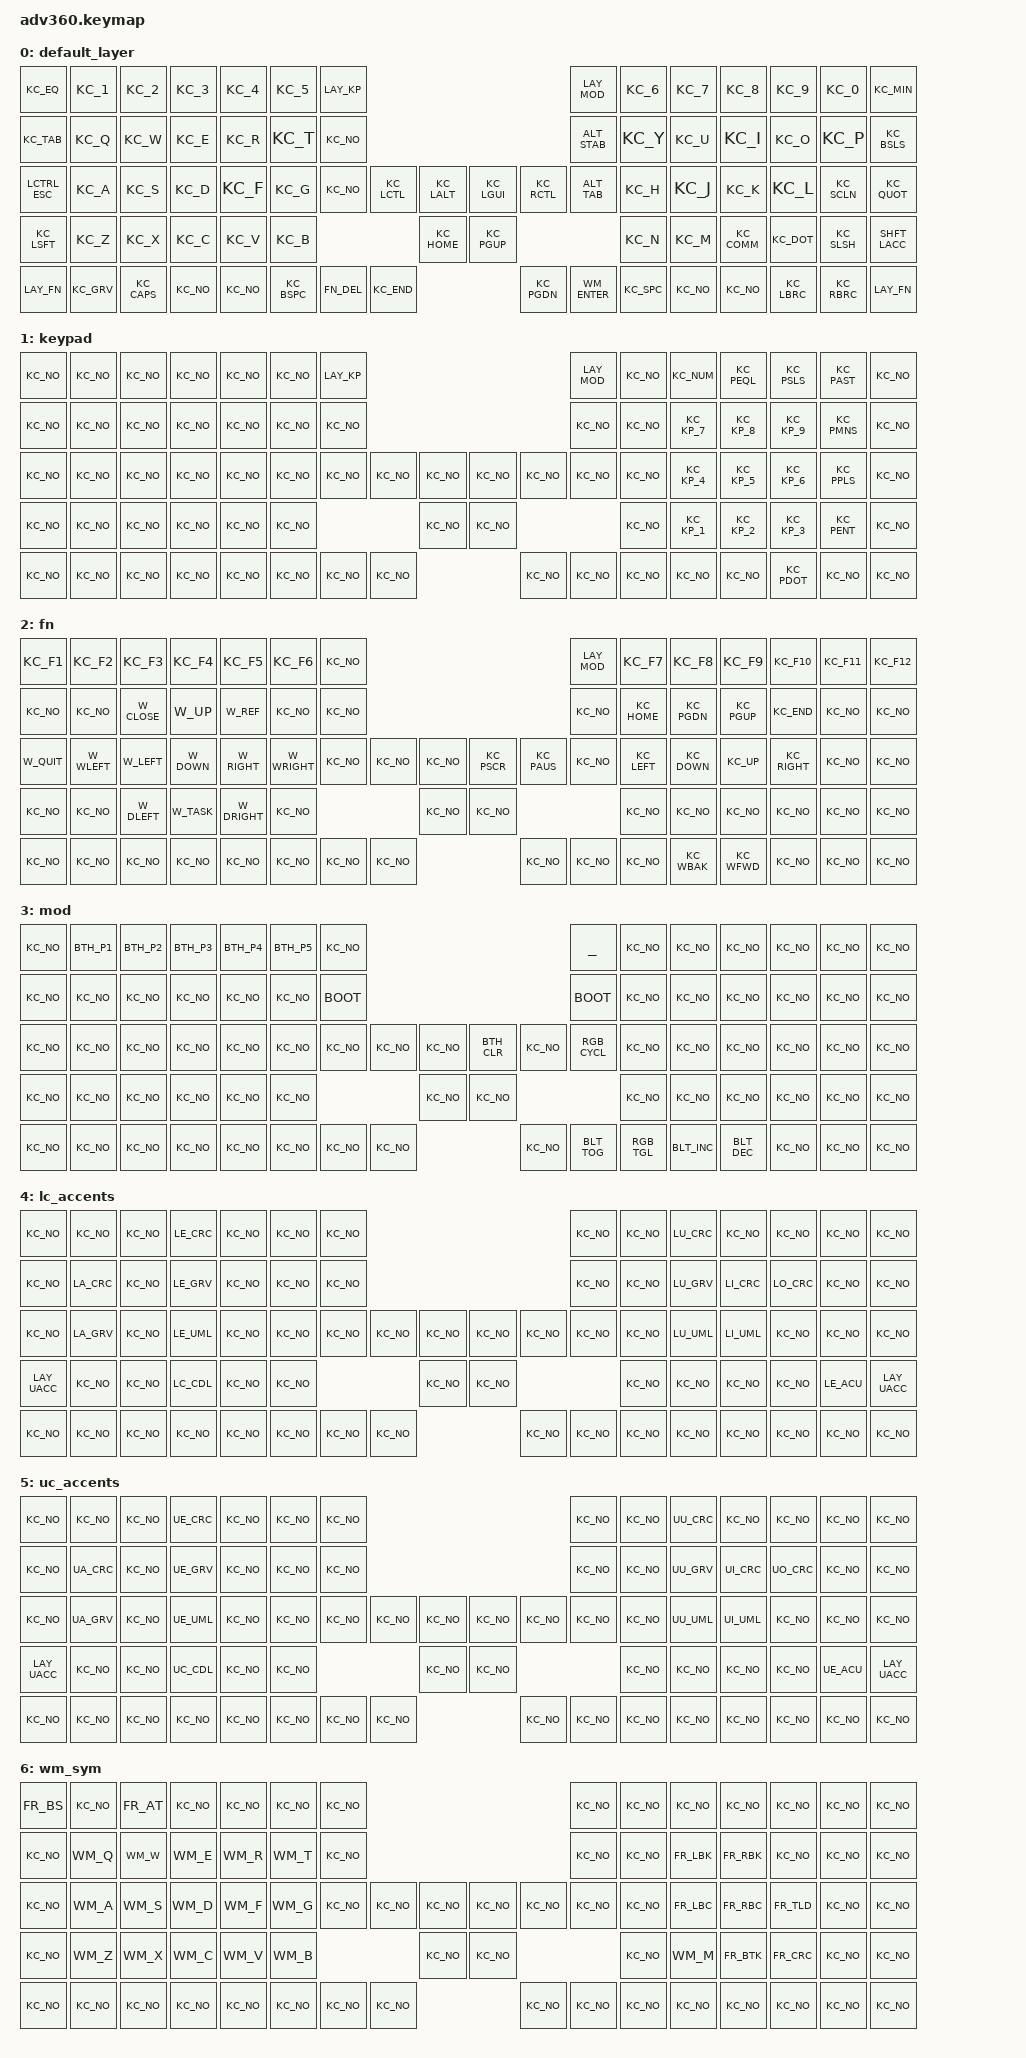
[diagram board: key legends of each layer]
#include <behaviors.dtsi>
#include <dt-bindings/zmk/backlight.h>
#include <dt-bindings/zmk/bt.h>
#include <dt-bindings/zmk/keys.h>
#include <dt-bindings/zmk/rgb.h>

#include "user_constants.h"

/ {
    behaviors {
        #include "user_behaviors.dtsi"
    };

    macros {
        #include "user_macros.dtsi"
    };

    keymap {
        compatible = "zmk,keymap";

        default_layer {
            bindings = <
                /*=*/    KC_EQ      /*1*/ KC_1    /*2*/    KC_2     /*3*/    KC_3    /*4*/    KC_4     /*5*/ KC_5     /*KP*/  LAY_KP                                       /**/                                        /*MOD*/ LAY_MOD  /*6*/ KC_6     /*7*/    KC_7     /*8*/    KC_8     /*9*/ KC_9     /*0*/ KC_0     /*-*/    KC_MIN
                /*TAB*/  KC_TAB     /*Q*/ KC_Q    /*W*/    KC_W     /*E*/    KC_E    /*R*/    KC_R     /*T*/ KC_T     /*HK1*/ KC_NO                                        /**/                                        /*HK3*/ ALT_STAB /*Y*/ KC_Y     /*U*/    KC_U     /*I*/    KC_I     /*O*/ KC_O     /*P*/ KC_P     /*\*/    KC_BSLS
                /*ESC*/  LCTRL_ESC  /*A*/ KC_A    /*S*/    KC_S     /*D*/    KC_D    /*F*/    KC_F     /*G*/ KC_G     /*HK2*/ KC_NO    /*CTRL*/ KC_LCTL  /*ALT*/  KC_LALT  /**/  /*WIN*/  KC_LGUI   /*CTRL*/ KC_RCTL   /*HK4*/ ALT_TAB  /*H*/ KC_H     /*J*/    KC_J     /*K*/    KC_K     /*L*/ KC_L     /*;*/ KC_SCLN  /*'*/    KC_QUOT
                /*SHFT*/ KC_LSFT    /*Z*/ KC_Z    /*X*/    KC_X     /*C*/    KC_C    /*V*/    KC_V     /*B*/ KC_B                                        /*HOME*/ KC_HOME  /**/  /*PGUP*/ KC_PGUP                                       /*N*/ KC_N     /*M*/    KC_M     /*,*/    KC_COMM  /*.*/ KC_DOT   /*/*/ KC_SLSH  /*SHFT*/ SHFT_LACC
                /*FN*/   LAY_FN     /*`*/ KC_GRV  /*CAPS*/ KC_CAPS  /*LARR*/ KC_NO   /*RARR*/ KC_NO                   /*SPC*/ KC_BSPC  /*DEL*/  FN_DEL   /*END*/  KC_END   /**/  /*PGDN*/ KC_PGDN   /*ENT*/ WM_ENTER   /*SPC*/ KC_SPC                  /*UARR*/ KC_NO    /*DARR*/ KC_NO    /*[*/ KC_LBRC  /*]*/ KC_RBRC  /*FN*/   LAY_FN
            >;
        };

        keypad {
            bindings = <
                /*=*/    KC_NO      /*1*/ KC_NO   /*2*/    KC_NO    /*3*/    KC_NO   /*4*/    KC_NO    /*5*/ KC_NO    /*KP*/  LAY_KP                                       /**/                                        /*MOD*/ LAY_MOD  /*6*/ KC_NO    /*7*/    KC_NUM   /*8*/    KC_PEQL  /*9*/ KC_PSLS  /*0*/ KC_PAST  /*-*/    KC_NO
                /*TAB*/  KC_NO      /*Q*/ KC_NO   /*W*/    KC_NO    /*E*/    KC_NO   /*R*/    KC_NO    /*T*/ KC_NO    /*HK1*/ KC_NO                                        /**/                                        /*HK3*/ KC_NO    /*Y*/ KC_NO    /*U*/    KC_KP_7  /*I*/    KC_KP_8  /*O*/ KC_KP_9  /*P*/ KC_PMNS  /*\*/    KC_NO
                /*ESC*/  KC_NO      /*A*/ KC_NO   /*S*/    KC_NO    /*D*/    KC_NO   /*F*/    KC_NO    /*G*/ KC_NO    /*HK2*/ KC_NO    /*CTRL*/ KC_NO    /*ALT*/  KC_NO    /**/  /*WIN*/  KC_NO     /*CTRL*/ KC_NO     /*HK4*/ KC_NO    /*H*/ KC_NO    /*J*/    KC_KP_4  /*K*/    KC_KP_5  /*L*/ KC_KP_6  /*;*/ KC_PPLS  /*'*/    KC_NO
                /*SHFT*/ KC_NO      /*Z*/ KC_NO   /*X*/    KC_NO    /*C*/    KC_NO   /*V*/    KC_NO    /*B*/ KC_NO                                       /*HOME*/ KC_NO    /**/  /*PGUP*/ KC_NO                                         /*N*/ KC_NO    /*M*/    KC_KP_1  /*,*/    KC_KP_2  /*.*/ KC_KP_3  /*/*/ KC_PENT  /*SHFT*/ KC_NO
                /*FN*/   KC_NO      /*`*/ KC_NO   /*CAPS*/ KC_NO    /*LARR*/ KC_NO   /*RARR*/ KC_NO                   /*SPC*/ KC_NO    /*DEL*/  KC_NO    /*END*/  KC_NO    /**/  /*PGDN*/ KC_NO     /*ENT*/  KC_NO     /*SPC*/ KC_NO                   /*UARR*/ KC_NO    /*DARR*/ KC_NO    /*[*/ KC_PDOT  /*]*/ KC_NO    /*FN*/   KC_NO
            >;
        };

        fn {
            bindings = <
                /*=*/    KC_F1      /*1*/ KC_F2   /*2*/    KC_F3    /*3*/    KC_F4   /*4*/    KC_F5    /*5*/ KC_F6    /*KP*/  KC_NO                                        /**/                                        /*MOD*/ LAY_MOD  /*6*/ KC_F7    /*7*/    KC_F8    /*8*/    KC_F9    /*9*/ KC_F10   /*0*/ KC_F11   /*-*/    KC_F12
                /*TAB*/  KC_NO      /*Q*/ KC_NO   /*W*/    W_CLOSE  /*E*/    W_UP    /*R*/    W_REF    /*T*/ KC_NO    /*HK1*/ KC_NO                                        /**/                                        /*HK3*/ KC_NO    /*Y*/ KC_HOME  /*U*/    KC_PGDN  /*I*/    KC_PGUP  /*O*/ KC_END   /*P*/ KC_NO    /*\*/    KC_NO
                /*ESC*/  W_QUIT     /*A*/ W_WLEFT /*S*/    W_LEFT   /*D*/    W_DOWN  /*F*/    W_RIGHT  /*G*/ W_WRIGHT /*HK2*/ KC_NO    /*CTRL*/ KC_NO    /*ALT*/  KC_NO    /**/  /*WIN*/  KC_PSCR   /*CTRL*/ KC_PAUS   /*HK4*/ KC_NO    /*H*/ KC_LEFT  /*J*/    KC_DOWN  /*K*/    KC_UP    /*L*/ KC_RIGHT /*;*/ KC_NO    /*'*/    KC_NO
                /*SHFT*/ KC_NO      /*Z*/ KC_NO   /*X*/    W_DLEFT  /*C*/    W_TASK  /*V*/    W_DRIGHT /*B*/ KC_NO                                       /*HOME*/ KC_NO    /**/  /*PGUP*/ KC_NO                                         /*N*/ KC_NO    /*M*/    KC_NO    /*,*/    KC_NO    /*.*/ KC_NO    /*/*/ KC_NO    /*SHFT*/ KC_NO
                /*FN*/   KC_NO      /*`*/ KC_NO   /*CAPS*/ KC_NO    /*LARR*/ KC_NO   /*RARR*/ KC_NO                   /*SPC*/ KC_NO    /*DEL*/  KC_NO    /*END*/  KC_NO    /**/  /*PGDN*/ KC_NO     /*ENT*/  KC_NO     /*SPC*/ KC_NO                   /*UARR*/ KC_WBAK  /*DARR*/ KC_WFWD  /*[*/ KC_NO    /*]*/ KC_NO    /*FN*/   KC_NO
            >;
        };

        mod {
            bindings = <
                /*=*/    KC_NO      /*1*/ BTH_P1  /*2*/    BTH_P2   /*3*/    BTH_P3  /*4*/    BTH_P4   /*5*/ BTH_P5   /*KP*/  KC_NO                                        /**/                                        /*MOD*/ _______  /*6*/ KC_NO    /*7*/    KC_NO    /*8*/    KC_NO    /*9*/ KC_NO    /*0*/ KC_NO    /*-*/    KC_NO
                /*TAB*/  KC_NO      /*Q*/ KC_NO   /*W*/    KC_NO    /*E*/    KC_NO   /*R*/    KC_NO    /*T*/ KC_NO    /*HK1*/ BOOT                                         /**/                                        /*HK3*/ BOOT     /*Y*/ KC_NO    /*U*/    KC_NO    /*I*/    KC_NO    /*O*/ KC_NO    /*P*/ KC_NO    /*\*/    KC_NO
                /*ESC*/  KC_NO      /*A*/ KC_NO   /*S*/    KC_NO    /*D*/    KC_NO   /*F*/    KC_NO    /*G*/ KC_NO    /*HK2*/ KC_NO    /*CTRL*/ KC_NO    /*ALT*/  KC_NO    /**/  /*WIN*/  BTH_CLR   /*CTRL*/ KC_NO     /*HK4*/ RGB_CYCL /*H*/ KC_NO    /*J*/    KC_NO    /*K*/    KC_NO    /*L*/ KC_NO    /*;*/ KC_NO    /*'*/    KC_NO
                /*SHFT*/ KC_NO      /*Z*/ KC_NO   /*X*/    KC_NO    /*C*/    KC_NO   /*V*/    KC_NO    /*B*/ KC_NO                                       /*HOME*/ KC_NO    /**/  /*PGUP*/ KC_NO                                         /*N*/ KC_NO    /*M*/    KC_NO    /*,*/    KC_NO    /*.*/ KC_NO    /*/*/ KC_NO    /*SHFT*/ KC_NO
                /*FN*/   KC_NO      /*`*/ KC_NO   /*CAPS*/ KC_NO    /*LARR*/ KC_NO   /*RARR*/ KC_NO                   /*SPC*/ KC_NO    /*DEL*/  KC_NO    /*END*/  KC_NO    /**/  /*PGDN*/ KC_NO     /*ENT*/  BLT_TOG   /*SPC*/ RGB_TGL                 /*UARR*/ BLT_INC  /*DARR*/ BLT_DEC  /*[*/ KC_NO    /*]*/ KC_NO    /*FN*/   KC_NO
            >;
        };

        lc_accents {
            bindings = <
                /*=*/    KC_NO      /*1*/ KC_NO   /*2*/    KC_NO    /*3*/    LE_CRC  /*4*/    KC_NO    /*5*/ KC_NO    /*KP*/  KC_NO                                        /**/                                        /*MOD*/ KC_NO    /*6*/ KC_NO    /*7*/    LU_CRC   /*8*/    KC_NO    /*9*/ KC_NO    /*0*/ KC_NO    /*-*/    KC_NO
                /*TAB*/  KC_NO      /*Q*/ LA_CRC  /*W*/    KC_NO    /*E*/    LE_GRV  /*R*/    KC_NO    /*T*/ KC_NO    /*HK1*/ KC_NO                                        /**/                                        /*HK3*/ KC_NO    /*Y*/ KC_NO    /*U*/    LU_GRV   /*I*/    LI_CRC   /*O*/ LO_CRC   /*P*/ KC_NO    /*\*/    KC_NO
                /*ESC*/  KC_NO      /*A*/ LA_GRV  /*S*/    KC_NO    /*D*/    LE_UML  /*F*/    KC_NO    /*G*/ KC_NO    /*HK2*/ KC_NO    /*CTRL*/ KC_NO    /*ALT*/  KC_NO    /**/  /*WIN*/  KC_NO     /*CTRL*/ KC_NO     /*HK4*/ KC_NO    /*H*/ KC_NO    /*J*/    LU_UML   /*K*/    LI_UML   /*L*/ KC_NO    /*;*/ KC_NO    /*'*/    KC_NO
                /*SHFT*/ LAY_UACC   /*Z*/ KC_NO   /*X*/    KC_NO    /*C*/    LC_CDL  /*V*/    KC_NO    /*B*/ KC_NO                                       /*HOME*/ KC_NO    /**/  /*PGUP*/ KC_NO                                         /*N*/ KC_NO    /*M*/    KC_NO    /*,*/    KC_NO    /*.*/ KC_NO    /*/*/ LE_ACU   /*SHFT*/ LAY_UACC
                /*FN*/   KC_NO      /*`*/ KC_NO   /*CAPS*/ KC_NO    /*LARR*/ KC_NO   /*RARR*/ KC_NO                   /*SPC*/ KC_NO    /*DEL*/  KC_NO    /*END*/  KC_NO    /**/  /*PGDN*/ KC_NO     /*ENT*/  KC_NO     /*SPC*/ KC_NO                   /*UARR*/ KC_NO    /*DARR*/ KC_NO    /*[*/ KC_NO    /*]*/ KC_NO    /*FN*/   KC_NO
            >;
        };

        uc_accents {
            bindings = <
                /*=*/    KC_NO      /*1*/ KC_NO   /*2*/    KC_NO    /*3*/    UE_CRC  /*4*/    KC_NO    /*5*/ KC_NO    /*KP*/  KC_NO                                        /**/                                        /*MOD*/ KC_NO    /*6*/ KC_NO    /*7*/    UU_CRC   /*8*/    KC_NO    /*9*/ KC_NO    /*0*/ KC_NO    /*-*/    KC_NO
                /*TAB*/  KC_NO      /*Q*/ UA_CRC  /*W*/    KC_NO    /*E*/    UE_GRV  /*R*/    KC_NO    /*T*/ KC_NO    /*HK1*/ KC_NO                                        /**/                                        /*HK3*/ KC_NO    /*Y*/ KC_NO    /*U*/    UU_GRV   /*I*/    UI_CRC   /*O*/ UO_CRC   /*P*/ KC_NO    /*\*/    KC_NO
                /*ESC*/  KC_NO      /*A*/ UA_GRV  /*S*/    KC_NO    /*D*/    UE_UML  /*F*/    KC_NO    /*G*/ KC_NO    /*HK2*/ KC_NO    /*CTRL*/ KC_NO    /*ALT*/  KC_NO    /**/  /*WIN*/  KC_NO     /*CTRL*/ KC_NO     /*HK4*/ KC_NO    /*H*/ KC_NO    /*J*/    UU_UML   /*K*/    UI_UML   /*L*/ KC_NO    /*;*/ KC_NO    /*'*/    KC_NO
                /*SHFT*/ LAY_UACC   /*Z*/ KC_NO   /*X*/    KC_NO    /*C*/    UC_CDL  /*V*/    KC_NO    /*B*/ KC_NO                                       /*HOME*/ KC_NO    /**/  /*PGUP*/ KC_NO                                         /*N*/ KC_NO    /*M*/    KC_NO    /*,*/    KC_NO    /*.*/ KC_NO    /*/*/ UE_ACU   /*SHFT*/ LAY_UACC
                /*FN*/   KC_NO      /*`*/ KC_NO   /*CAPS*/ KC_NO    /*LARR*/ KC_NO   /*RARR*/ KC_NO                   /*SPC*/ KC_NO    /*DEL*/  KC_NO    /*END*/  KC_NO    /**/  /*PGDN*/ KC_NO     /*ENT*/  KC_NO     /*SPC*/ KC_NO                   /*UARR*/ KC_NO    /*DARR*/ KC_NO    /*[*/ KC_NO    /*]*/ KC_NO    /*FN*/   KC_NO
            >;
        };

        wm_sym {
            bindings = <
                /*=*/    FR_BS      /*1*/ KC_NO   /*2*/    FR_AT    /*3*/    KC_NO   /*4*/    KC_NO    /*5*/ KC_NO    /*KP*/  KC_NO                                                                                    /*MOD*/ KC_NO    /*6*/ KC_NO    /*7*/    KC_NO    /*8*/    KC_NO    /*9*/ KC_NO    /*0*/ KC_NO    /*-*/    KC_NO
                /*TAB*/  KC_NO      /*Q*/ WM_Q    /*W*/    WM_W     /*E*/    WM_E    /*R*/    WM_R     /*T*/ WM_T     /*HK1*/ KC_NO                                                                                    /*HK3*/ KC_NO    /*Y*/ KC_NO    /*U*/    FR_LBK   /*I*/    FR_RBK   /*O*/ KC_NO    /*P*/ KC_NO    /*\*/    KC_NO
                /*ESC*/  KC_NO      /*A*/ WM_A    /*S*/    WM_S     /*D*/    WM_D    /*F*/    WM_F     /*G*/ WM_G     /*HK2*/ KC_NO    /*CTRL*/ KC_NO    /*ALT*/  KC_NO          /*WIN*/  KC_NO     /*CTRL*/ KC_NO     /*HK4*/ KC_NO    /*H*/ KC_NO    /*J*/    FR_LBC   /*K*/    FR_RBC   /*L*/ FR_TLD   /*;*/ KC_NO    /*'*/    KC_NO
                /*SHFT*/ KC_NO      /*Z*/ WM_Z    /*X*/    WM_X     /*C*/    WM_C    /*V*/    WM_V     /*B*/ WM_B                                        /*HOME*/ KC_NO          /*PGUP*/ KC_NO                                         /*N*/ KC_NO    /*M*/    WM_M     /*,*/    FR_BTK   /*.*/ FR_CRC   /*/*/ KC_NO    /*SHFT*/ KC_NO
                /*FN*/   KC_NO      /*`*/ KC_NO   /*CAPS*/ KC_NO    /*LARR*/ KC_NO   /*RARR*/ KC_NO                   /*SPC*/ KC_NO    /*DEL*/  KC_NO    /*END*/  KC_NO          /*PGDN*/ KC_NO     /*ENT*/ KC_NO      /*SPC*/ KC_NO                   /*UARR*/ KC_NO    /*DARR*/ KC_NO    /*[*/ KC_NO    /*]*/ KC_NO    /*FN*/   KC_NO
            >;
        };
    };
};
